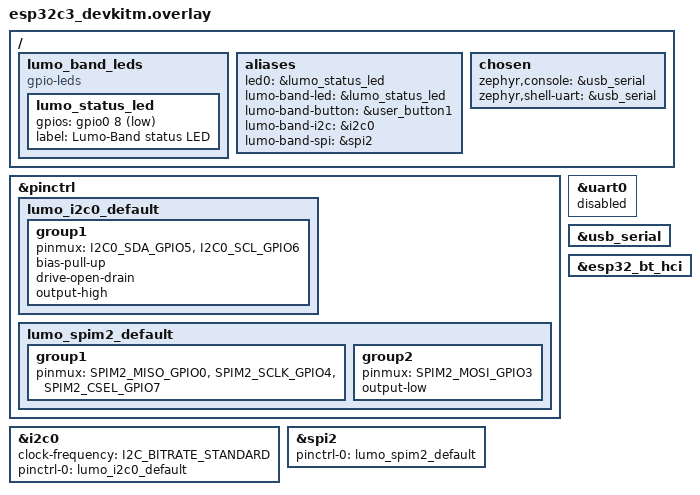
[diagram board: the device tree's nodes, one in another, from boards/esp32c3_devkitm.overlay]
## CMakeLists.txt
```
cmake_minimum_required(VERSION 3.20.0)
# Make the app-local board definition discoverable by west/Zephyr.
list(APPEND BOARD_ROOT ${CMAKE_CURRENT_LIST_DIR})
find_package(Zephyr REQUIRED HINTS $ENV{ZEPHYR_BASE})
project(lumo_band)

target_include_directories(app PRIVATE include)
target_sources(app PRIVATE
  src/main.c
  src/lumo_ble.c
  src/esp32_link.c
)
```

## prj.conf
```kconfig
CONFIG_BT=y
CONFIG_BT_PERIPHERAL=y
CONFIG_BT_DEVICE_NAME="LUMO-BAND"
CONFIG_BT_DEVICE_APPEARANCE=0
CONFIG_BT_MAX_CONN=1
CONFIG_BT_SETTINGS=y
CONFIG_SETTINGS=y
CONFIG_BT_GATT_DYNAMIC_DB=n
CONFIG_BT_CTLR_PHY_2M=y

CONFIG_LOG=y
CONFIG_LOG_DEFAULT_LEVEL=3
CONFIG_PRINTK=y

CONFIG_GPIO=y
CONFIG_SERIAL=y
CONFIG_UART_CONSOLE=y
CONFIG_CONSOLE=y
CONFIG_CBPRINTF_FP_SUPPORT=n

# Keep the application usable on boards without a hardware watchdog.
CONFIG_WATCHDOG=n
```

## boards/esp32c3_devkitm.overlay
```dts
/*
 * Compatibility overlay: build the Lumo-Band SuperMini pin map against the
 * upstream esp32c3_devkitm target as requested by the migration checklist.
 */

#include <zephyr/dt-bindings/gpio/gpio.h>
#include <zephyr/dt-bindings/pinctrl/esp-pinctrl-common.h>
#include <dt-bindings/pinctrl/esp32c3-pinctrl.h>
#include <zephyr/dt-bindings/pinctrl/esp32c3-gpio-sigmap.h>

/ {
    lumo_band_leds {
        compatible = "gpio-leds";

        lumo_status_led: lumo_status_led {
            gpios = <&gpio0 8 GPIO_ACTIVE_LOW>;
            label = "Lumo-Band status LED";
        };
    };

    aliases {
        led0 = &lumo_status_led;
        lumo-band-led = &lumo_status_led;
        lumo-band-button = &user_button1;
        lumo-band-i2c = &i2c0;
        lumo-band-spi = &spi2;
    };

    chosen {
        /* ESP32-C3 SuperMini exposes the native USB Serial/JTAG peripheral. */
        zephyr,console = &usb_serial;
        zephyr,shell-uart = &usb_serial;
    };
};

&pinctrl {
    lumo_i2c0_default: lumo_i2c0_default {
        group1 {
            /* TODO: Confirm these pins against the assembled sensor PCB. */
            pinmux = <I2C0_SDA_GPIO5>,
                     <I2C0_SCL_GPIO6>;
            bias-pull-up;
            drive-open-drain;
            output-high;
        };
    };

    lumo_spim2_default: lumo_spim2_default {
        group1 {
            pinmux = <SPIM2_MISO_GPIO0>,
                     <SPIM2_SCLK_GPIO4>,
                     <SPIM2_CSEL_GPIO7>;
        };
        group2 {
            pinmux = <SPIM2_MOSI_GPIO3>;
            output-low;
        };
    };
};

&uart0 {
    status = "disabled";
};

&usb_serial {
    status = "okay";
};

&i2c0 {
    status = "okay";
    clock-frequency = <I2C_BITRATE_STANDARD>;
    pinctrl-0 = <&lumo_i2c0_default>;
    pinctrl-names = "default";
};

&spi2 {
    status = "okay";
    pinctrl-0 = <&lumo_spim2_default>;
    pinctrl-names = "default";
};

&esp32_bt_hci {
    status = "okay";
};
```

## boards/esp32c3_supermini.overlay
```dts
/*
 * Lumo-Band signal map for the ESP32-C3 SuperMini.
 *
 * The upstream board already maps LED to GPIO8 and BOOT button to GPIO9.
 * Sensor devices are not present in the current application yet, so this
 * overlay reserves buses only. Add each sensor node when its exact part and
 * address are known.
 */

#include <zephyr/dt-bindings/pinctrl/esp-pinctrl-common.h>
#include <dt-bindings/pinctrl/esp32c3-pinctrl.h>
#include <zephyr/dt-bindings/pinctrl/esp32c3-gpio-sigmap.h>

/ {
    aliases {
        lumo-band-led = &blue_led_0;
        lumo-band-button = &user_button1;
        lumo-band-i2c = &i2c0;
        lumo-band-spi = &spi2;
    };
};

&pinctrl {
    lumo_i2c0_default: lumo_i2c0_default {
        group1 {
            /* TODO: Confirm these pins against the assembled sensor PCB. */
            pinmux = <I2C0_SDA_GPIO5>,
                     <I2C0_SCL_GPIO6>;
            bias-pull-up;
            drive-open-drain;
            output-high;
        };
    };

    lumo_spim2_default: lumo_spim2_default {
        group1 {
            /* GPIO2, GPIO8 and GPIO9 are strapping pins and are avoided. */
            pinmux = <SPIM2_MISO_GPIO0>,
                     <SPIM2_SCLK_GPIO4>,
                     <SPIM2_CSEL_GPIO7>;
        };
        group2 {
            pinmux = <SPIM2_MOSI_GPIO3>;
            output-low;
        };
    };
};

&i2c0 {
    status = "okay";
    clock-frequency = <I2C_BITRATE_STANDARD>;
    pinctrl-0 = <&lumo_i2c0_default>;
    pinctrl-names = "default";
};

&spi2 {
    status = "okay";
    pinctrl-0 = <&lumo_spim2_default>;
    pinctrl-names = "default";
};

&esp32_bt_hci {
    status = "okay";
};
```

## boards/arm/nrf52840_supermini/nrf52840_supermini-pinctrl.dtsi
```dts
/* SPDX-License-Identifier: Apache-2.0 */

&pinctrl {
    uart0_default: uart0_default {
        group1 {
            psels = <NRF_PSEL(UART_TX, 0, 6)>,
                     <NRF_PSEL(UART_RX, 0, 8)>;
            bias-pull-up;
        };
    };

    uart0_sleep: uart0_sleep {
        group1 {
            psels = <NRF_PSEL(UART_TX, 0, 6)>,
                     <NRF_PSEL(UART_RX, 0, 8)>;
            low-power-enable;
        };
    };
};
```

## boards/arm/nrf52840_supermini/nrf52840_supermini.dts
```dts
/* SPDX-License-Identifier: Apache-2.0 */

/dts-v1/;
#include <nordic/nrf52840_qiaa.dtsi>
#include <nordic/nrf52840_partition.dtsi>
#include "nrf52840_supermini-pinctrl.dtsi"

/ {
    model = "nRF52840 Super Mini";
    compatible = "custom,nrf52840-supermini";

    chosen {
        zephyr,console = &uart0;
        zephyr,shell-uart = &uart0;
        zephyr,uart-mcumgr = &uart0;
    };

    leds {
        compatible = "gpio-leds";

        /* Common Super Mini status LED. Change this pin if your board differs. */
        led0: led_0 {
            gpios = <&gpio0 13 GPIO_ACTIVE_LOW>;
            label = "Status LED";
        };
    };

    aliases {
        led0 = &led0;
    };
};

&gpio0 {
    status = "okay";
};

&gpio1 {
    status = "okay";
};

&uicr {
    gpio-as-nreset;
};

&gpiote {
    status = "okay";
};

&uart0 {
    compatible = "nordic,nrf-uarte";
    status = "okay";
    current-speed = <115200>;
    pinctrl-0 = <&uart0_default>;
    pinctrl-1 = <&uart0_sleep>;
    pinctrl-names = "default", "sleep";
};

&usbd {
    compatible = "nordic,nrf-usbd";
    status = "okay";
};
```

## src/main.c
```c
#include <inttypes.h>

#include "esp_log.h"
#include "freertos/FreeRTOS.h"
#include "freertos/task.h"

static const char *TAG = "lumo_band";

void app_main(void)
{
    uint32_t counter = 0;

    ESP_LOGI(TAG, "================================");
    ESP_LOGI(TAG, " LUMO-BAND ESP32-C3 SUPERMINI");
    ESP_LOGI(TAG, " ESP-IDF flash and console OK");
    ESP_LOGI(TAG, "================================");

    while (1) {
        ESP_LOGI(TAG, "Lumo-Band running: %" PRIu32 " second(s)", counter++);
        vTaskDelay(pdMS_TO_TICKS(1000));
    }
}
```

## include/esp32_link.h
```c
#ifndef ESP32_LINK_H
#define ESP32_LINK_H

#include <stddef.h>
#include <stdint.h>

int lumo_esp32_link_init(void);
int lumo_esp32_link_send(const uint8_t *data, size_t len);

#endif /* ESP32_LINK_H */
```

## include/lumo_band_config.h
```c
#ifndef LUMO_BAND_CONFIG_H
#define LUMO_BAND_CONFIG_H

/*
 * The ESP32-C3 band is a BLE peripheral. A phone or companion hub scans and
 * connects as a BLE central, subscribes to TX, and writes commands to RX.
 */
#define LUMO_BAND_DEVICE_NAME "LUMO-BAND"

/* Keep these UUIDs in sync with every phone/hub BLE client. */
#define LUMO_BAND_SERVICE_UUID \
    "7c5a0001-5d5a-4f7b-8c3a-6a6d2e8f1001"
#define LUMO_BAND_TX_UUID \
    "7c5a0002-5d5a-4f7b-8c3a-6a6d2e8f1001"
#define LUMO_BAND_RX_UUID \
    "7c5a0003-5d5a-4f7b-8c3a-6a6d2e8f1001"

/* Select the peer transport here. BLE is the production default. */
#define LUMO_LINK_TRANSPORT_BLE 0
#define LUMO_LINK_TRANSPORT_UART 1
#define LUMO_LINK_TRANSPORT_CUSTOM 2

#define LUMO_ESP32_LINK_TRANSPORT LUMO_LINK_TRANSPORT_BLE

/* TODO: Fill these in when the physical link is selected. */
#define LUMO_ESP32_UART_LABEL "TODO_COMPANION_UART"
#define LUMO_ESP32_UART_BAUDRATE 115200
#define LUMO_ESP32_BLE_PEER_ADDRESS "TODO: optional bonded peer address"

#endif /* LUMO_BAND_CONFIG_H */
```

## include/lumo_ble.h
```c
#ifndef LUMO_BLE_H
#define LUMO_BLE_H

#include <stddef.h>
#include <stdint.h>

int lumo_ble_init(void);
int lumo_ble_notify(const uint8_t *data, size_t len);

#endif /* LUMO_BLE_H */
```

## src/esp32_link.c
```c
#include "esp_log.h"

#include "esp32_link.h"
#include "lumo_band_config.h"
#include "lumo_ble.h"

static const char *TAG = "lumo_link";

esp_err_t lumo_esp32_link_init(void)
{
    /*
     * BLE transport is implemented by lumo_ble.c. A phone or companion hub
     * acts as the central and connects to LUMO_BAND_SERVICE_UUID.
     *
     * TODO: If UART or another transport is selected, initialize it here.
     * TODO: Add framing, authentication, retry and offline queue policy.
     */
    ESP_LOGI(TAG, "BLE peer transport selected: %d", LUMO_ESP32_LINK_TRANSPORT);
    return ESP_OK;
}

esp_err_t lumo_esp32_link_send(const uint8_t *data, size_t len)
{
    /* Route messages through the selected transport. */
#if LUMO_ESP32_LINK_TRANSPORT == LUMO_LINK_TRANSPORT_BLE
    return lumo_ble_notify(data, len);
#elif LUMO_ESP32_LINK_TRANSPORT == LUMO_LINK_TRANSPORT_UART
    /* TODO: Send a framed message through the optional companion UART. */
    (void)data;
    (void)len;
    return ESP_OK;
#else
    /* TODO: Add the custom transport implementation. */
    (void)data;
    (void)len;
    return ESP_OK;
#endif
}
```

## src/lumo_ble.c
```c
#include <errno.h>
#include <string.h>

#include <zephyr/bluetooth/bluetooth.h>
#include <zephyr/bluetooth/conn.h>
#include <zephyr/bluetooth/gatt.h>
#include <zephyr/bluetooth/hci.h>
#include <zephyr/bluetooth/uuid.h>
#include <zephyr/logging/log.h>

#include "lumo_band_config.h"
#include "lumo_ble.h"

LOG_MODULE_REGISTER(lumo_ble, LOG_LEVEL_INF);

#define LUMO_UUID_BYTES \
    BT_UUID_128_ENCODE(0x7c5a0001, 0x5d5a, 0x4f7b, 0x8c3a, 0x6a6d2e8f1001ULL)
#define LUMO_TX_UUID_BYTES \
    BT_UUID_128_ENCODE(0x7c5a0002, 0x5d5a, 0x4f7b, 0x8c3a, 0x6a6d2e8f1001ULL)
#define LUMO_RX_UUID_BYTES \
    BT_UUID_128_ENCODE(0x7c5a0003, 0x5d5a, 0x4f7b, 0x8c3a, 0x6a6d2e8f1001ULL)

static struct bt_conn *current_conn;
static bool tx_subscribed;

static struct bt_uuid_128 service_uuid = BT_UUID_INIT_128(LUMO_UUID_BYTES);
static struct bt_uuid_128 tx_uuid = BT_UUID_INIT_128(LUMO_TX_UUID_BYTES);
static struct bt_uuid_128 rx_uuid = BT_UUID_INIT_128(LUMO_RX_UUID_BYTES);

static ssize_t rx_write(struct bt_conn *conn,
                        const struct bt_gatt_attr *attr,
                        const void *buf,
                        uint16_t len,
                        uint16_t offset,
                        uint8_t flags)
{
    ARG_UNUSED(conn);
    ARG_UNUSED(attr);
    ARG_UNUSED(flags);

    if (offset != 0U) {
        return BT_GATT_ERR(BT_ATT_ERR_INVALID_OFFSET);
    }

    LOG_INF("Received %u bytes from BLE peer", len);
    LOG_HEXDUMP_INF(buf, len, "BLE peer command");
    /* TODO: Decode commands from the phone or companion hub here. */
    return len;
}

static void tx_ccc_changed(const struct bt_gatt_attr *attr, uint16_t value)
{
    ARG_UNUSED(attr);
    tx_subscribed = (value == BT_GATT_CCC_NOTIFY);
    LOG_INF("BLE peer notifications %s", tx_subscribed ? "enabled" : "disabled");
}

BT_GATT_SERVICE_DEFINE(lumo_service,
    BT_GATT_PRIMARY_SERVICE(&service_uuid.uuid),
    BT_GATT_CHARACTERISTIC(&tx_uuid.uuid,
                           BT_GATT_CHRC_NOTIFY,
                           BT_GATT_PERM_NONE,
                           NULL, NULL, NULL),
    BT_GATT_CCC(tx_ccc_changed,
                BT_GATT_PERM_READ | BT_GATT_PERM_WRITE),
    BT_GATT_CHARACTERISTIC(&rx_uuid.uuid,
                           BT_GATT_CHRC_WRITE | BT_GATT_CHRC_WRITE_WITHOUT_RESP,
                           BT_GATT_PERM_WRITE,
                           NULL, rx_write, NULL)
);

static const struct bt_data ad[] = {
    BT_DATA_BYTES(BT_DATA_FLAGS, (BT_LE_AD_GENERAL | BT_LE_AD_NO_BREDR)),
    BT_DATA(BT_DATA_NAME_COMPLETE,
            CONFIG_BT_DEVICE_NAME, sizeof(CONFIG_BT_DEVICE_NAME) - 1),
    BT_DATA_BYTES(BT_DATA_UUID128_ALL, LUMO_UUID_BYTES),
};

static void connected(struct bt_conn *conn, uint8_t err)
{
    if (err) {
        LOG_ERR("BLE connection failed (%u)", err);
        return;
    }

    current_conn = bt_conn_ref(conn);
    LOG_INF("BLE peer connected");
}

static void disconnected(struct bt_conn *conn, uint8_t reason)
{
    ARG_UNUSED(conn);
    LOG_INF("BLE peer disconnected (reason 0x%02x)", reason);

    if (current_conn) {
        bt_conn_unref(current_conn);
        current_conn = NULL;
    }
    tx_subscribed = false;

    (void)bt_le_adv_start(BT_LE_ADV_PARAM(BT_LE_ADV_OPT_CONN,
                                          BT_GAP_ADV_FAST_INT_MIN_2,
                                          BT_GAP_ADV_FAST_INT_MAX_2,
                                          NULL),
                          ad, ARRAY_SIZE(ad), NULL, 0);
}

BT_CONN_CB_DEFINE(lumo_conn_callbacks) = {
    .connected = connected,
    .disconnected = disconnected,
};

static void bt_ready(int err)
{
    if (err) {
        LOG_ERR("Bluetooth enable failed (%d)", err);
        return;
    }

    err = bt_le_adv_start(BT_LE_ADV_PARAM(BT_LE_ADV_OPT_CONN,
                                          BT_GAP_ADV_FAST_INT_MIN_2,
                                          BT_GAP_ADV_FAST_INT_MAX_2,
                                          NULL),
                          ad, ARRAY_SIZE(ad), NULL, 0);
    if (err) {
        LOG_ERR("Advertising start failed (%d)", err);
        return;
    }

    LOG_INF("Advertising as %s", CONFIG_BT_DEVICE_NAME);
}

int lumo_ble_init(void)
{
    return bt_enable(bt_ready);
}

int lumo_ble_notify(const uint8_t *data, size_t len)
{
    if (!current_conn || !tx_subscribed) {
        return -ENOTCONN;
    }

    return bt_gatt_notify(current_conn, &lumo_service.attrs[2], data, len);
}
```
